VERSION ""

NS_ :

BS_:

BU_:

BO_ 768 AMS_HEARTBEAT_ID: 7 Vector__XXX
 SG_ ams_heatbeat_state : 0|8@1+ (1,0) [0|0] "" Vector__XXX
 SG_ ams_heartbeat_counter : 8|8@1+ (1,0) [0|0] "" Vector__XXX

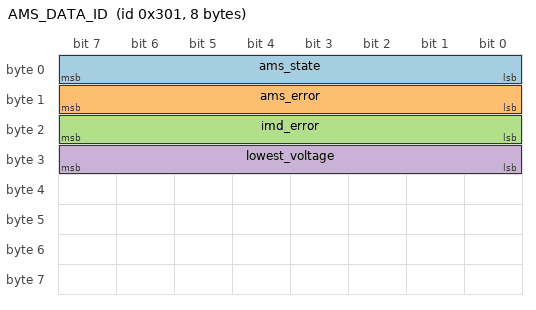
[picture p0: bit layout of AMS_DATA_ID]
BO_ 769 AMS_DATA_ID: 8 Vector__XXX
 SG_ ams_state : 0|8@1+ (1,0) [0|0] "" Vector__XXX
 SG_ ams_error : 8|8@1+ (1,0) [0|0] "" Vector__XXX
 SG_ imd_error : 16|8@1+ (1,0) [0|0] "" Vector__XXX
 SG_ lowest_voltage : 24|8@1+ (1,0) [0|0] "" Vector__XXX
